AUTOSAR XML (schema 4-1-3)
standard types defined: boolean, uint16, boolean_CompuMethod, boolean_DataConstr, uint16_DataConstr, uint32, uint8
package /DataTypes
  impl type rt_Arry_uint16_10: category=ARRAY
    element rt_Arry_uint16_10: array-size=10, array-size-semantics=FIXED-SIZE, implementation-data-type=ImplementationDataTypes/uint16
package /RB/ApplicationSW/PT/CompuMethods
  compu method CM_boolean: 0=FALSE, 1=TRUE
package /RB/ApplicationSW/PT/Units
  unit NoUnit: factor-si-to-unit=1, offset-si-to-unit=0
package /UAES/ASW/DataConstrs
  range DC_boolean: raw 0..1
  range DC_uint16: raw 0..65535
  range DC_uint32: raw 0..4294967295
  range DC_uint8: raw 0..255
package /UAES/ASW/DataTypeMappingSets
  data type mapping set DTMS_EPBCalprDrvr_DD
package /UAES/ASW/ImplementationDataTypes
  impl type Array_uint16_10: category=ARRAY
    element Array_uint16_10: array-size=10, array-size-semantics=FIXED-SIZE, implementation-data-type=ImplementationDataTypes/uint16
  impl type Array_uint32_2: category=ARRAY
    element Array_uint32_2: array-size=2, array-size-semantics=FIXED-SIZE, implementation-data-type=uint32
package /UAES/ASW/PortInterfaces
  client server interface IoHwAb_EPBHb
    9 x operation, all with possible-error=E_NOT_OK:
      Get_AD_Valid
        arg EPB_AD_Valid: category=VALUE, type=ImplementationDataTypes/boolean, direction=OUT
      Get_CS1_Val
        arg cs1_Val: category=ARRAY, type=rt_Arry_uint16_10, direction=OUT
      Get_CS2_Val
        arg cs2_Val: category=ARRAY, type=rt_Arry_uint16_10, direction=OUT
      Get_Diag
        arg EPBDiag_status: category=ARRAY, type=Array_uint32_2, direction=OUT
      Get_SH1_Val
        arg sh1_Val: category=ARRAY, type=Array_uint16_10, direction=OUT
      Get_SH2_Val
        arg sh2_Val: category=ARRAY, type=Array_uint16_10, direction=OUT
      Get_uBridge_Val
        arg uBridge_Val: category=ARRAY, type=Array_uint16_10, direction=OUT
      Set_Mod
        arg Hb_Mod: category=VALUE, type=uint8, direction=IN
      Set_Safemod
        arg Safemode_Mod: category=VALUE, type=ImplementationDataTypes/boolean, direction=IN
    error E_NOT_OK: error-code=1
  5 x sender receiver interface:
    EPBCalprDrvr_flgClsdDrvrMos: invalidation-policy{data-element=EPBCalprDrvr_flgClsdDrvrMos/Val, handle-invalid=DONT-INVALIDATE}
      data Val: category=VALUE, sw-calibration-access=READ-ONLY, type=ImplementationDataTypes/boolean
    EPBCalprDrvr_flgSsmEnaLockLine: invalidation-policy{data-element=EPBCalprDrvr_flgSsmEnaLockLine/Val, handle-invalid=DONT-INVALIDATE}
      data Val: category=VALUE, sw-calibration-access=READ-ONLY, type=ImplementationDataTypes/boolean
    EPBCalprDrvr_flgSsmEnaRlesLine: invalidation-policy{data-element=EPBCalprDrvr_flgSsmEnaRlesLine/Val, handle-invalid=DONT-INVALIDATE}
      data Val: category=VALUE, sw-calibration-access=READ-ONLY, type=ImplementationDataTypes/boolean
    EPBCalprDrvr_stHwDrvrCmd: invalidation-policy{data-element=EPBCalprDrvr_stHwDrvrCmd/Val, handle-invalid=DONT-INVALIDATE}
      data Val: category=VALUE, sw-calibration-access=READ-ONLY, type=uint8
    EPBCalprDrvr_stMotCmd: invalidation-policy{data-element=EPBCalprDrvr_stMotCmd/Val, handle-invalid=DONT-INVALIDATE}
      data Val: category=VALUE, sw-calibration-access=READ-ONLY, type=uint8
package /UAES/ASW/SwComponentTypes
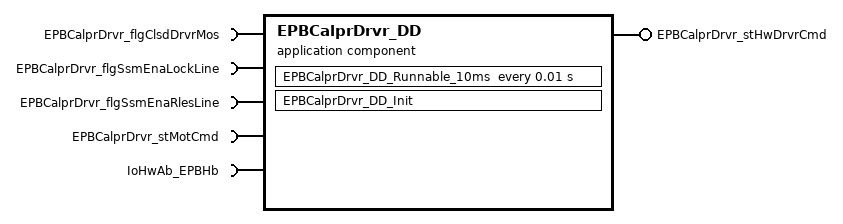
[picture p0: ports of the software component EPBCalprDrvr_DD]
  application sw component type EPBCalprDrvr_DD
    4 x require port:
      EPBCalprDrvr_flgClsdDrvrMos: nonqueued-receiver-com-spec{data-element=EPBCalprDrvr_flgClsdDrvrMos/Val, init-value=ComSpecd4b92df6_2fff877570301aa3:0}, required-interface=EPBCalprDrvr_flgClsdDrvrMos
      EPBCalprDrvr_flgSsmEnaLockLine: nonqueued-receiver-com-spec{data-element=EPBCalprDrvr_flgSsmEnaLockLine/Val, init-value=ComSpecbdc4641e_c3dc40990d6930d8:0}, required-interface=EPBCalprDrvr_flgSsmEnaLockLine
      EPBCalprDrvr_flgSsmEnaRlesLine: nonqueued-receiver-com-spec{data-element=EPBCalprDrvr_flgSsmEnaRlesLine/Val, init-value=ComSpecd6a2c134_07a3ba93a1b3c057:0}, required-interface=EPBCalprDrvr_flgSsmEnaRlesLine
      EPBCalprDrvr_stMotCmd: nonqueued-receiver-com-spec{data-element=EPBCalprDrvr_stMotCmd/Val, init-value=ComSpec810ba193_fc016d4d18965f8f:0}, required-interface=EPBCalprDrvr_stMotCmd
    provide port EPBCalprDrvr_stHwDrvrCmd: nonqueued-sender-com-spec{data-element=EPBCalprDrvr_stHwDrvrCmd/Val, init-value=ComSpecd9402e56_5b24e47dc704ae01:0}, provided-interface=EPBCalprDrvr_stHwDrvrCmd
    require port IoHwAb_EPBHb: required-interface=IoHwAb_EPBHb
    behavior EPBCalprDrvr_DD_InternalBehavior: data-type-mapping=DTMS_EPBCalprDrvr_DD, handle-termination-and-restart=NO-SUPPORT
      ar-typed-per-instance-memorys:
        data EPBCal_EPBCalprDrvr_stMotSpiCmd: category=VALUE, sw-calibration-access=READ-ONLY, type=uint8
        data EPBCal_EPBCalprDrvr_flgSafeClsd: category=VALUE, sw-calibration-access=READ-ONLY, type=ImplementationDataTypes/boolean
        data EPBCal_EPBCalprDrvr_flgMotIoCmd: category=VALUE, sw-calibration-access=READ-ONLY, type=ImplementationDataTypes/boolean
      init event EPBCalprDrvr_DD_InitEvent: start-on-event=EPBCalprDrvr_DD_Init
      timing event TMT_EPBCalprDrvr_DD_Runnable_10ms: start-on-event=EPBCalprDrvr_DD_Runnable_10ms, period=0.01
      runnable EPBCalprDrvr_DD_Init
      runnable EPBCalprDrvr_DD_Runnable_10ms
        data-read-access:
          4 x access:
            IN_EPBCalprDrvr_flgClsdDrvrMos_Val: accessed-variable=EPBCalprDrvr_flgClsdDrvrMos.Val
            IN_EPBCalprDrvr_flgSsmEnaLockLine_Val: accessed-variable=EPBCalprDrvr_flgSsmEnaLockLine.Val
            IN_EPBCalprDrvr_flgSsmEnaRlesLine_Val: accessed-variable=EPBCalprDrvr_flgSsmEnaRlesLine.Val
            IN_EPBCalprDrvr_stMotCmd_Val: accessed-variable=EPBCalprDrvr_stMotCmd.Val
        data-write-access:
          access OUT_EPBCalprDrvr_stHwDrvrCmd_Val: accessed-variable=EPBCalprDrvr_stHwDrvrCmd.Val
        sync call SC_IoHwAb_EPBHb_Set_Mod: operation=IoHwAb_EPBHb.Set_Mod, timeout=0
        sync call SC_IoHwAb_EPBHb_Set_Safemod: operation=IoHwAb_EPBHb.Set_Safemod, timeout=0
  swc implementation EPBCalprDrvr_DD_imp: programming-language=C, sw-version=1.10.1, used-code-generator=Embedded Coder 7.5 (R2020b) 29-Jul-2020, vendor-id=0, behavior=EPBCalprDrvr_DD_InternalBehavior
    code-descriptors:
      code Code
        artifact-descriptors:
          short-label=EPBCalprDrvr_DD_c, category=SWSRC
          short-label=EPBCalprDrvr_DD_h, category=SWHDR
          short-label=EPBCalprDrvr_DD_private_h, category=SWHDR
          short-label=EPBCalprDrvr_DD_types_h, category=SWHDR
          short-label=rtwtypes_h, category=SWHDR
    resource consumption RsrcCons_EPBCalprDrvr_DD
